# R7FA6T2BD register map
Vendor: Renesas Electronics Corporation; Series: RA6; File version: 1.40.00
CPU: CM33 r0p4, little endian, MPU, FPU, VTOR, 4 interrupt priority bits, 96 interrupts
Registers are 32-bit, read-write, reset 0x0 unless marked. A register's access mark holds for its fields unless they carry their own. Offsets are from the block's base; [hi:lo] are bit positions; {n}, {i} and the like mark numbered series; 'fields as' and 'values as' point back to an identical list.

## GPT_GTCLK — GTCLK
Base 0x40169B00
0x00 GTCLKCR — General PWM Timer Clock Control Register
  [0] BPEN — Synchronization Circuit Bypass Enable
    0=In case of using Bus Clock and GPT Core Clock asynchronously; 1=In case of using Bus Clock and GPT Core Clock synchronously

## PDG — PWM Delay Generation Circuit
Base 0x4016A000
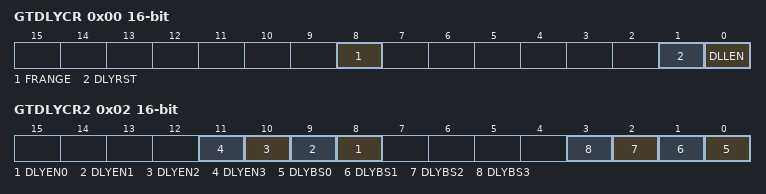
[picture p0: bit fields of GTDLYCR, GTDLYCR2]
0x00 GTDLYCR 16-bit — PWM Output Delay Control Register
  [8] FRANGE — GPT core clock Frequency Range
    0=GPT core clock frequency is 115 MHz to 200 MHz; 1=GPT core clock frequency is 80 MHz to 120 MHz
  [1] DLYRST — PWM Delay Generation Circuit Reset
    0=Normal operation; 1=Reset
  [0] DLLEN — DLL Operation Enable
    0=DLL operation disabled; 1=DLL operation enabled
0x02 GTDLYCR2 16-bit — PWM Output Delay Control Register 2
  [n+8] DLYEN{n} (n=0..3) — PWM Delay Generation Circuit enable for channel {n}
    0=Delay generation circuit of channel {n} enabled; 1=Delay generation circuit of channel {n} disabled
  [n] DLYBS{n} (n=0..3) — PWM Delay Generation Circuit bypass for channel {n}
    0=Delay generation circuit of channel {n} bypassed; 1=Delay generation circuit of channel {n} not bypassed
{0x18+4i} GTDLYR{i}A (i=0..3) 16-bit — GTIOCnA Rising Output Delay Register
  [4:0] DLY — GTIOCnA Output Rising Edge Delay Setting
    0=Delay on rising edges is not applied; {v}=Delay of {v}/32 times GTCLK period applied (v=1..31)
{0x1A+4i} GTDLYR{i}B (i=0..3) 16-bit — GTIOCnB Rising Output Delay Register
  [4:0] DLY — GTIOCnB Output Rising Edge Delay Setting
    values as GTDLYR0A.DLY
{0x28+4i} GTDLYF{i}A (i=0..3) 16-bit — GTIOCnA Falling Output Delay Register
  [4:0] DLY — GTIOCnA Output Falling Edge Delay Setting
    0=Delay on falling edges is not applied; {v}=Delay of {v}/32 times GTCLK period applied (v=1..31)
{0x2A+4i} GTDLYF{i}B (i=0..3) 16-bit — GTIOCnB Falling Output Delay Register
  [4:0] DLY — GTIOCnB Output Falling Edge Delay Setting
    values as GTDLYF0A.DLY

## DAC120 — 12-bit D/A converter 0
Base 0x40172000
Same registers: DAC121 0x40172100
{0x0+2i} DADR{i} (i=0..1) 16-bit — D/A Data Register {i}
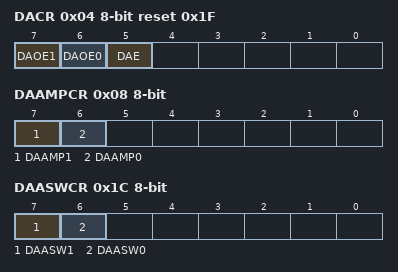
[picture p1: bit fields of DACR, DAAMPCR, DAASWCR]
0x04 DACR 8-bit reset 0x1F — D/A Control Register
  [7] DAOE1 — D/A Output Enable 1
    0=Disable analog output of channel 1 (DA1) Disable analog output of channel 3 (DA3); 1=Enable D/A conversion of channel 1 (DA1) Enable D/A conversion of channel 3 (DA3)
  [6] DAOE0 — D/A Output Enable 0
    0=Disable analog output of channel 0 (DA0) Disable analog output of channel 2 (DA2); 1=Enable D/A conversion of channel 0 (DA0) Enable D/A conversion of channel 2 (DA2)
  [5] DAE — D/A Enable
    0=Control D/A conversion of channels 0 and 1 individually Control D/A conversion of channels 2 and 3 individually; 1=Control D/A conversion of channels 0 and 1 collectively Control D/A conversion of channels 2 and 3 collectively
0x05 DADPR 8-bit — DADRn Format Select Register
  [7] DPSEL — DADRn Format Select
    0=Right-justified format; 1=Left-justified format
0x08 DAAMPCR 8-bit — D/A Output Amplifier Control Register
  [7] DAAMP1 — Amplifier Control 1
    0=Do not use channel 1 output amplifier (m = 0) Do not use channel 3 output amplifier (m = 1); 1=Use channel 1 output amplifier (m = 0) Use channel 3 output amplifier (m = 1)
  [6] DAAMP0 — Amplifier Control 0
    0=Do not use channel 0 output amplifier (m = 0) Do not use channel 2 output amplifier (m = 1); 1=Use channel 0 output amplifier (m = 0) Use channel 2 output amplifier (m = 1)
0x1C DAASWCR 8-bit — D/A Amplifier Stabilization Wait Control Register
  [7] DAASW1 — D/A Amplifier Stabilization Wait 1 and D/A internal output control
    0=For output to external pin: Amplifier stabilization wait off (output) for channel 1 For output to internal module: Disable output for channel 1; 1=For output to external pin: Amplifier stabilization wait on (high-Z) for channel 1 For output to internal module: Enable output for channel 1
  [6] DAASW0 — D/A Amplifier Stabilization Wait 0 and D/A internal output control
    0=For output to external pin: Amplifier stabilization wait off (output) for channel 0 For output to internal module: Disable output for channel 0; 1=For output to external pin: Amplifier stabilization wait on (high-Z) for channel 0 For output to internal module: Enable output for channel 0

## TSD — Temperature Sensor Calibration Data
Base 0x407FB000
0x17C TSCDR ro (reset mask 0xFFFF0000) — Temperature Sensor Calibration Data Register
  [15:0] TSCDR — Temperature Sensor Calibration Data

## FLAD — Data Flash
Base 0x407FC000
0x40 FCKMHZ 8-bit reset 0x3C — Data Flash Access Frequency Register
